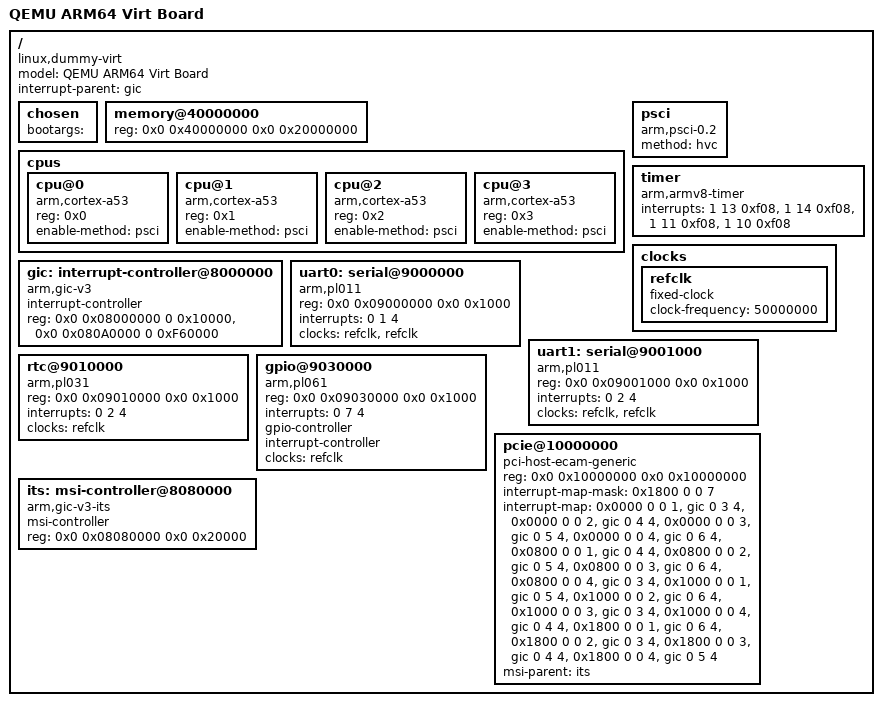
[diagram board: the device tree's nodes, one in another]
/*
 * Copyright (C) 2023-2024 胡启航<Nick Hu>
 *
 * Author: 胡启航<Nick Hu>
 *
 * Email: huqihan@live.com
 */

/dts-v1/;

/ {
    compatible = "linux,dummy-virt";
    model = "QEMU ARM64 Virt Board";
    #address-cells = <2>;
    #size-cells = <2>;

    interrupt-parent = <&gic>;

    chosen {
        bootargs = "";
    };

    memory@40000000 {
        device_type = "memory";
        reg = <0x0 0x40000000 0x0 0x20000000>;  /* 512MB RAM */
    };

    cpus {
        #address-cells = <1>;
        #size-cells = <0>;

        cpu@0 {
            compatible = "arm,cortex-a53";
            device_type = "cpu";
            reg = <0x0>;
            enable-method = "psci";
        };

        cpu@1 {
            compatible = "arm,cortex-a53";
            device_type = "cpu";
            reg = <0x1>;
            enable-method = "psci";
        };

        cpu@2 {
            compatible = "arm,cortex-a53";
            device_type = "cpu";
            reg = <0x2>;
            enable-method = "psci";
        };

        cpu@3 {
            compatible = "arm,cortex-a53";
            device_type = "cpu";
            reg = <0x3>;
            enable-method = "psci";
        };
    };

    psci {
        compatible = "arm,psci-0.2";
        method = "hvc";
    };

    timer {
        compatible = "arm,armv8-timer";
        interrupts = <1 13 0xf08>,  /* Secure Physical Timer */
                     <1 14 0xf08>,  /* Non-secure Physical Timer */
                     <1 11 0xf08>,  /* Virtual Timer */
                     <1 10 0xf08>;  /* Hypervisor Timer */
    };

    clocks {
        refclk: refclk {
            compatible = "fixed-clock";
            #clock-cells = <0>;
            clock-frequency = <50000000>;
        };
    };

    gic: interrupt-controller@8000000 {
        compatible = "arm,gic-v3";
        #interrupt-cells = <3>;
        interrupt-controller;
        reg = <0x0 0x08000000 0 0x10000>,  /* GICD */
              <0x0 0x080A0000 0 0xF60000>; /* GICR */
    };

    uart0: serial@9000000 {
        compatible = "arm,pl011";
        reg = <0x0 0x09000000 0x0 0x1000>;
        interrupts = <0 1 4>;  /* SPI 1, IRQ */
        clocks = <&refclk>, <&refclk>;
        clock-names = "uartclk", "apb_pclk";
    };

    uart1: serial@9001000 {
        compatible = "arm,pl011";
        reg = <0x0 0x09001000 0x0 0x1000>;
        interrupts = <0 2 4>;  /* SPI 2, IRQ */
        clocks = <&refclk>, <&refclk>;
        clock-names = "uartclk", "apb_pclk";
    };

    rtc@9010000 {
        compatible = "arm,pl031";
        reg = <0x0 0x09010000 0x0 0x1000>;
        interrupts = <0 2 4>;
        clocks = <&refclk>;
    };

    gpio@9030000 {
        compatible = "arm,pl061";
        reg = <0x0 0x09030000 0x0 0x1000>;
        interrupts = <0 7 4>;
        gpio-controller;
        #gpio-cells = <2>;
        interrupt-controller;
        #interrupt-cells = <2>;
        clocks = <&refclk>;
    };

    pcie@10000000 {
        compatible = "pci-host-ecam-generic";
        device_type = "pci";
        #address-cells = <3>;
        #size-cells = <2>;
        #interrupt-cells = <1>;
        reg = <0x0 0x10000000 0x0 0x10000000>;
        ranges = <0x1000000 0x0 0x00000000  0x0 0x3eff0000  0x0 0x00010000>,
                 <0x2000000 0x0 0x10000000  0x0 0x10000000  0x0 0x2eff0000>,
                 <0x3000000 0x80 0x00000000  0x80 0x00000000  0x80 0x00000000>;
        interrupt-map-mask = <0x1800 0 0 7>;
        interrupt-map = <0x0000 0 0 1 &gic 0 3 4>,
                        <0x0000 0 0 2 &gic 0 4 4>,
                        <0x0000 0 0 3 &gic 0 5 4>,
                        <0x0000 0 0 4 &gic 0 6 4>,
                        <0x0800 0 0 1 &gic 0 4 4>,
                        <0x0800 0 0 2 &gic 0 5 4>,
                        <0x0800 0 0 3 &gic 0 6 4>,
                        <0x0800 0 0 4 &gic 0 3 4>,
                        <0x1000 0 0 1 &gic 0 5 4>,
                        <0x1000 0 0 2 &gic 0 6 4>,
                        <0x1000 0 0 3 &gic 0 3 4>,
                        <0x1000 0 0 4 &gic 0 4 4>,
                        <0x1800 0 0 1 &gic 0 6 4>,
                        <0x1800 0 0 2 &gic 0 3 4>,
                        <0x1800 0 0 3 &gic 0 4 4>,
                        <0x1800 0 0 4 &gic 0 5 4>;
        msi-parent = <&its>;
    };

    its: msi-controller@8080000 {
        compatible = "arm,gic-v3-its";
        msi-controller;
        #msi-cells = <1>;
        reg = <0x0 0x08080000 0x0 0x20000>;
    };
};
